# PIC32CZ4010CA80176 register map
Vendor: Microchip Technology; Series: PIC32CZCA80; File version: 0
CPU: CM7 r1p1, selectable endian, MPU, FPU, 3 interrupt priority bits
Registers are 32-bit, read-write, reset 0x0 unless marked. A register's access mark holds for its fields unless they carry their own. Offsets are from the block's base; [hi:lo] are bit positions; lines under a group give offsets from that group; {n}, {i} and the like mark numbered series.

## CoreDebug
Base 0xE000ED00; register names take the prefix CoreDebug_
0x30 DFSR — Debug Fault Status Register
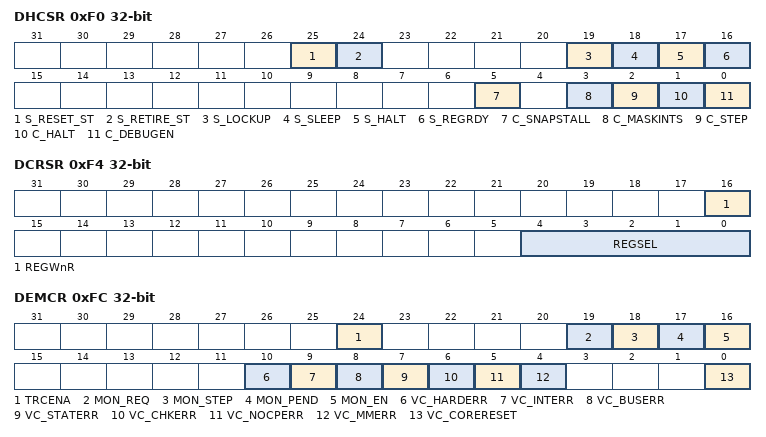
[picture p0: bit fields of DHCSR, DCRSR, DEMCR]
0xF0 DHCSR — Debug Halting Control and Status Register
  [25] S_RESET_ST, [24] S_RETIRE_ST, [19] S_LOCKUP, [18] S_SLEEP, [17] S_HALT, [16] S_REGRDY, [5] C_SNAPSTALL, [3] C_MASKINTS, [2] C_STEP, [1] C_HALT, [0] C_DEBUGEN
0xF4 DCRSR wo — Debug Core Register Selector Register
  [16] REGWnR, [4:0] REGSEL
0xF8 DCRDR — Debug Core Register Data Register
0xFC DEMCR — Debug Exception and Monitor Control Register
  [24] TRCENA, [19] MON_REQ, [18] MON_STEP, [17] MON_PEND, [16] MON_EN, [10] VC_HARDERR, [9] VC_INTERR, [8] VC_BUSERR, [7] VC_STATERR, [6] VC_CHKERR, [5] VC_NOCPERR, [4] VC_MMERR, [0] VC_CORERESET

## DWT — Data Watchpoint and Trace Register
Base 0xE0001000; register names take the prefix DWT_
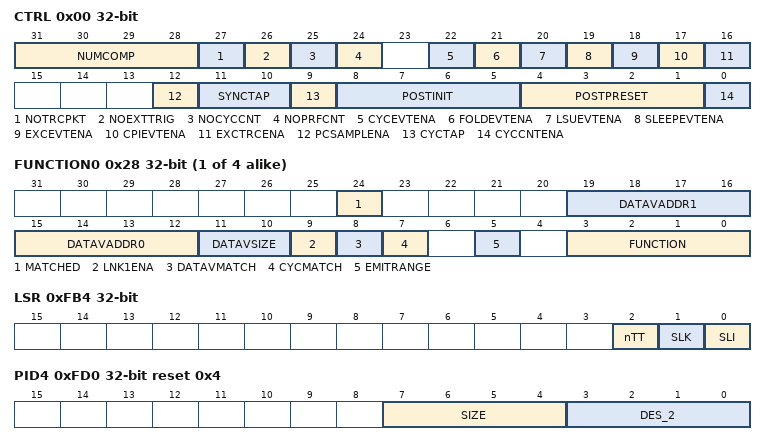
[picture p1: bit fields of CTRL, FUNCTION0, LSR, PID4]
0x00 CTRL — Control Register
  [31:28] NUMCOMP, [27] NOTRCPKT, [26] NOEXTTRIG, [25] NOCYCCNT, [24] NOPRFCNT, [22] CYCEVTENA, [21] FOLDEVTENA, [20] LSUEVTENA, [19] SLEEPEVTENA, [18] EXCEVTENA, [17] CPIEVTENA, [16] EXCTRCENA, [12] PCSAMPLENA, [11:10] SYNCTAP, [9] CYCTAP, [8:5] POSTINIT, [4:1] POSTPRESET, [0] CYCCNTENA
0x04 CYCCNT — Cycle Count Register
0x08 CPICNT — CPI Count Register
  [7:0] CPICNT
0x0C EXCCNT — Exception Overhead Count Register
  [7:0] EXCCNT
0x10 SLEEPCNT — Sleep Count Register
  [7:0] SLEEPCNT
0x14 LSUCNT — LSU Count Register
  [7:0] LSUCNT
0x18 FOLDCNT — Folded-instruction Count Register
  [7:0] FOLDCNT
0x1C PCSR ro — Program Counter Sample Register
{0x20+0x10*i} COMP{i} (i=0..3) — Comparator Register {i}
{0x24+0x10*i} MASK{i} (i=0..3) — Mask Register {i}
  [4:0] MASK
{0x28+0x10*i} FUNCTION{i} (i=0..3) — Function Register {i}
  [24] MATCHED, [19:16] DATAVADDR1, [15:12] DATAVADDR0, [11:10] DATAVSIZE, [9] LNK1ENA, [8] DATAVMATCH, [7] CYCMATCH, [5] EMITRANGE, [3:0] FUNCTION
0xFB0 LAR wo — DWT Software Lock Access Register
  [31:0] KEY — Lock access control
    0xC5ACCE55=UNLOCK (Unlock key value)
0xFB4 LSR ro — DWT Software Lock Status Register
  [2] nTT — Not thirty-two bit
  [1] SLK — Software Lock status
  [0] SLI — Software Lock implemented
0xFD0 PID4 ro reset 0x4 — DWT Peripheral Identification Register 4
  [7:4] SIZE — 4KB count
  [3:0] DES_2 — JEP106 continuation code
{0xFC0+4i} PID{i} ro (i=5..7) — DWT Peripheral Identification Register {i}
0xFE0 PID0 ro reset 0x2 — DWT Peripheral Identification Register 0
  [7:0] PART_0 — Part number bits[7:0]
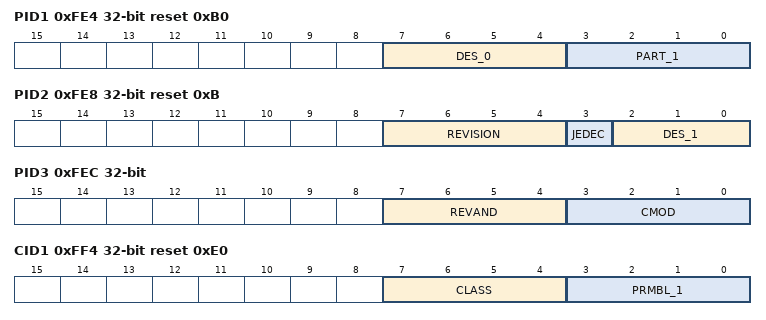
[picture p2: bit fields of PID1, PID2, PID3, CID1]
0xFE4 PID1 ro reset 0xB0 — DWT Peripheral Identification Register 1
  [7:4] DES_0 — JEP106 identification code bits [3:0]
  [3:0] PART_1 — Part number bits[11:8]
0xFE8 PID2 ro reset 0xB — DWT Peripheral Identification Register 2
  [7:4] REVISION — Component revision
  [3] JEDEC — JEDEC assignee value is used
  [2:0] DES_1 — JEP106 identification code bits[6:4]
0xFEC PID3 ro — DWT Peripheral Identification Register 3
  [7:4] REVAND
  [3:0] CMOD — Customer Modified
0xFF0 CID0 ro reset 0xD — DWT Component Identification Register 0
  [7:0] PRMBL_0 — CoreSight component identification preamble
0xFF4 CID1 ro reset 0xE0 — DWT Component Identification Register 1
  [7:4] CLASS — CoreSight component class
  [3:0] PRMBL_1 — CoreSight component identification preamble
0xFF8 CID2 ro reset 0x5 — DWT Component Identification Register 2
  [7:0] PRMBL_2 — CoreSight component identification preamble
0xFFC CID3 ro reset 0xB1 — DWT Component Identification Register 3
  [7:0] PRMBL_3 — CoreSight component identification preamble

## EBI — External Bus Interface
Base 0x458B0000; register names take the prefix EBI_
{0x0+0x10*i} CS_X[{i}] (i=0..3) group
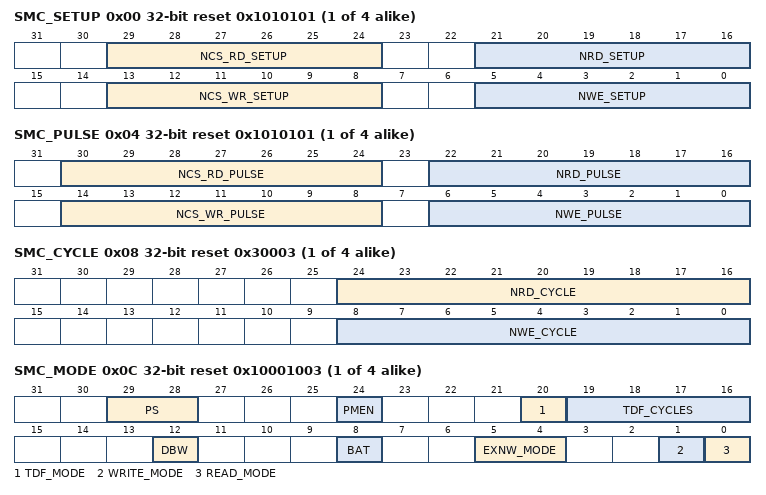
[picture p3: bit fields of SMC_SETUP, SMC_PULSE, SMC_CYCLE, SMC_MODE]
  0x00 SMC_SETUP reset 0x1010101
    [29:24] NCS_RD_SETUP — NCS Setup Length in READ Access
    [21:16] NRD_SETUP — NRD Setup Length
    [13:8] NCS_WR_SETUP — NCS Setup Length in WRITE Access
    [5:0] NWE_SETUP — NWE Setup Length
  0x04 SMC_PULSE reset 0x1010101
    [30:24] NCS_RD_PULSE — NCS Pulse Length in READ Access
    [22:16] NRD_PULSE — NRD Pulse Length
    [14:8] NCS_WR_PULSE — NCS Pulse Length in WRITE Access
    [6:0] NWE_PULSE — NWE Pulse Length
  0x08 SMC_CYCLE reset 0x30003
    [24:16] NRD_CYCLE — Total Read Cycle Length
    [8:0] NWE_CYCLE — Total Write Cycle Length
  0x0C SMC_MODE reset 0x10001003
    [29:28] PS — Page Size
      0=_4_BYTE (4-byte page); 1=_8_BYTE (8-byte page); 2=_16_BYTE (16-byte page); 3=_32_BYTE (32-byte page)
    [24] PMEN — Page Mode Enabled
    [20] TDF_MODE — TDF Optimization
    [19:16] TDF_CYCLES — Data Float Time
    [12] DBW — Data Bus Width
      0=_8_BIT (8-bit Data Bus); 1=_16_BIT (16-bit Data Bus)
    [8] BAT — Byte Access Type
      0=BYTE_SELECT (Byte select access type:- Write operation is controlled using NCS, NWE, NBS0, NBS1.- Read operation is controlled using NCS, NRD, NBS0, NBS1.); 1=BYTE_WRITE (Byte write access type:- Write operation is controlled using NCS, NWR0, NWR1.- Read operation is controlled using NCS and NRD.)
    [5:4] EXNW_MODE — NWAIT Mode
      0=DISABLED (Disabled-The NWAIT input signal is ignored on the corresponding chip select.); 2=FROZEN (Frozen Mode-If asserted, the NWAIT signal freezes the current read or write cycle. After deassertion, the read/write cycle is resumed from the point where it was stopped.); 3=READY (Ready Mode-The NWAIT signal indicates the availability of the external device at the end of the pulse of the controlling read or write signal, to complete the access. If high, the access normally completes. If low, the access is extended until NWAIT returns high.)
    [1] WRITE_MODE
    [0] READ_MODE
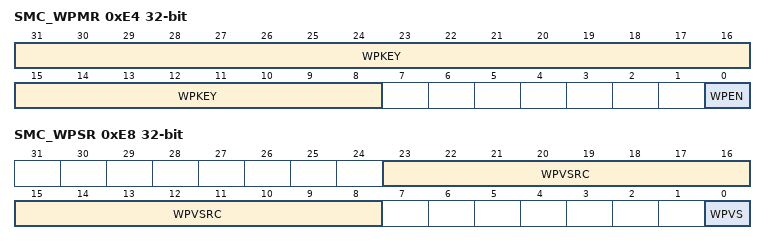
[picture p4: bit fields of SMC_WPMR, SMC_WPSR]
0xE4 SMC_WPMR — SMC Write Protection Mode Register
  [31:8] WPKEY — Write Protection Key
    0x534D43=PASSWD (Writing any other value in this field aborts the write operation of the WPEN bit. Always reads as 0.)
  [0] WPEN — Write Protect Enable
0xE8 SMC_WPSR ro — SMC Write Protection Status Register
  [23:8] WPVSRC — Write Protection Violation Source
  [0] WPVS — Write Protection Violation Status

## Notices in the file
Copyright (c) 2017 Microchip Technology Inc.
SPDX-License-Identifier: Apache-2.0
Licensed under the Apache License, Version 2.0 (the "License");
you may not use this file except in compliance with the License.
You may obtain a copy of the License at
http://www.apache.org/licenses/LICENSE-2.0
Unless required by applicable law or agreed to in writing, software
distributed under the License is distributed on an "AS IS" BASIS,
WITHOUT WARRANTIES OR CONDITIONS OF ANY KIND, either express or implied.
See the License for the specific language governing permissions and
limitations under the License.
